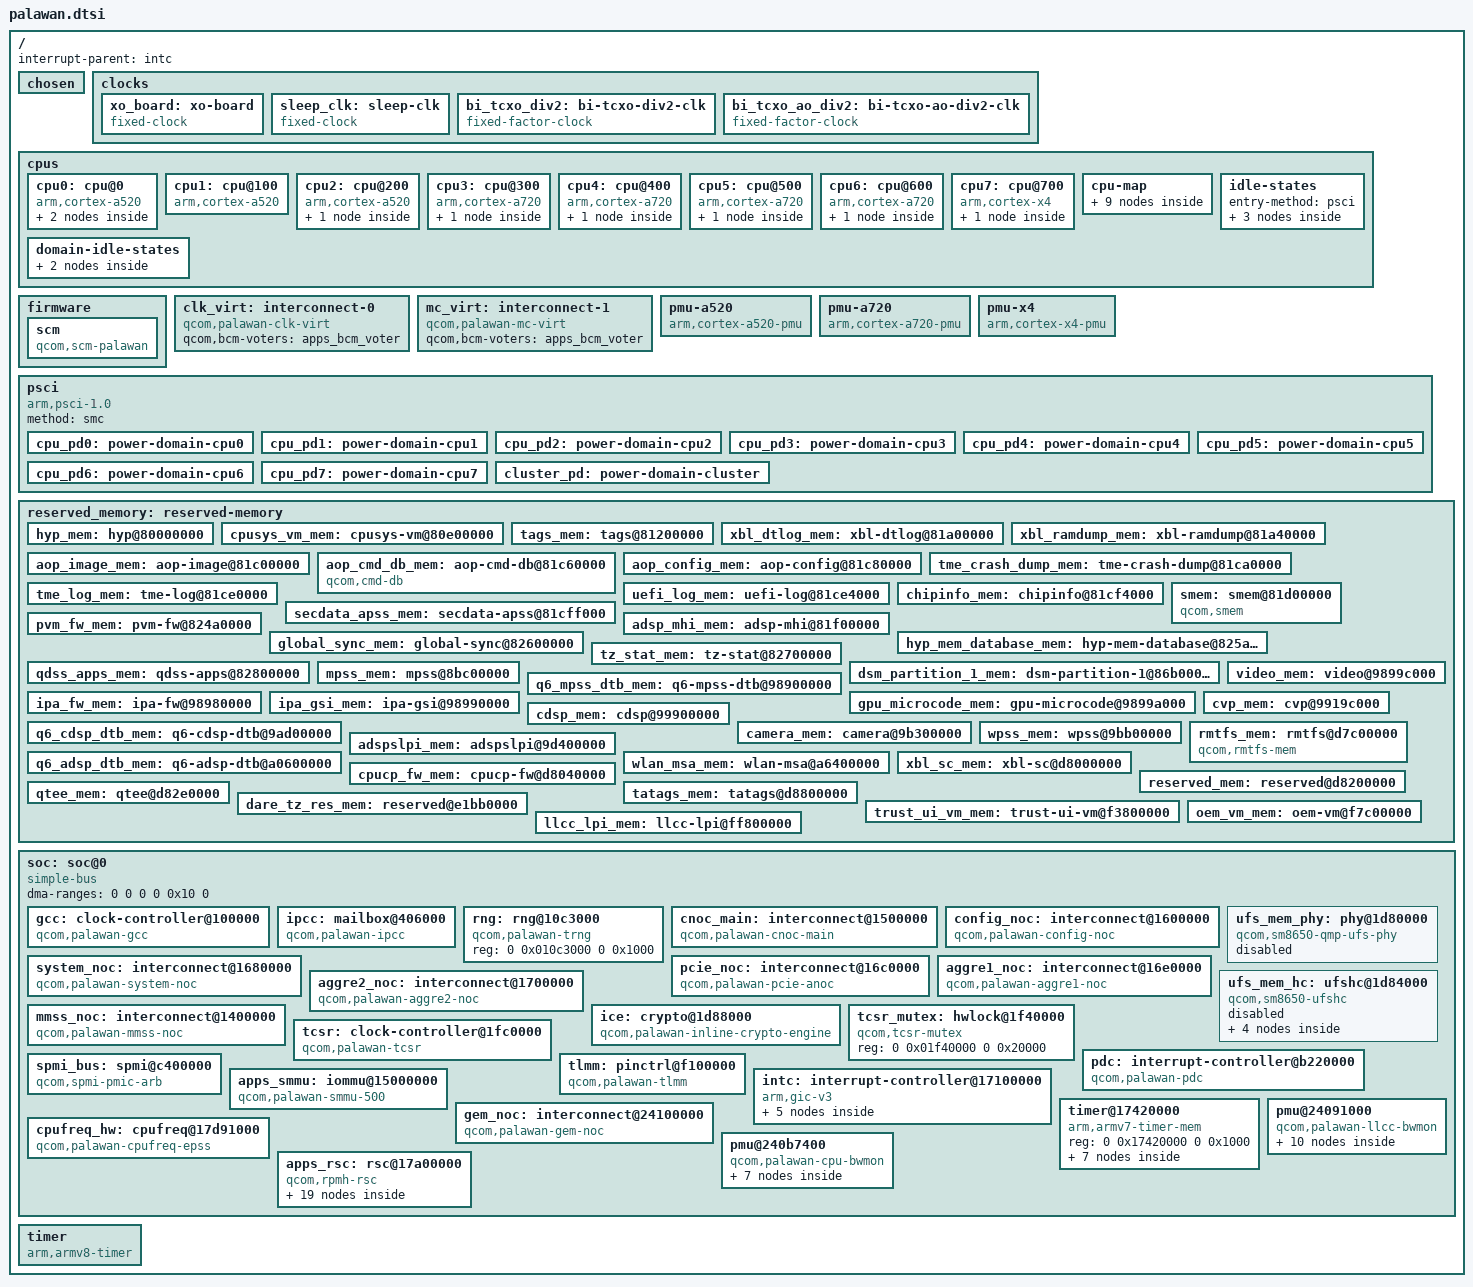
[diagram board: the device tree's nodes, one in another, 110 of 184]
// SPDX-License-Identifier: BSD-3-Clause
/*
 * Copyright (c) 2025, Alexandr Zubtsov <internal.hellhound@mainlining.org>
 */

#include <dt-bindings/clock/qcom,rpmh.h>
#include <dt-bindings/clock/qcom,palawan-gcc.h>
#include <dt-bindings/clock/qcom,sm8650-tcsr.h>
#include <dt-bindings/firmware/qcom,scm.h>
#include <dt-bindings/interconnect/qcom,icc.h>
#include <dt-bindings/interconnect/qcom,palawan-rpmh.h>
#include <dt-bindings/interrupt-controller/arm-gic.h>
#include <dt-bindings/mailbox/qcom-ipcc.h>
#include <dt-bindings/phy/phy-qcom-qmp.h>
#include <dt-bindings/power/qcom,rpmhpd.h>
#include <dt-bindings/power/qcom-rpmpd.h>
#include <dt-bindings/soc/qcom,rpmh-rsc.h>

/ {
	interrupt-parent = <&intc>;

	#address-cells = <2>;
	#size-cells = <2>;

	chosen { };

	clocks {
		xo_board: xo-board {
			compatible = "fixed-clock";
			#clock-cells = <0>;
		};

		sleep_clk: sleep-clk {
			compatible = "fixed-clock";
			#clock-cells = <0>;
		};

		bi_tcxo_div2: bi-tcxo-div2-clk {
			compatible = "fixed-factor-clock";
			#clock-cells = <0>;

			clocks = <&rpmhcc RPMH_CXO_CLK>;
			clock-mult = <1>;
			clock-div = <2>;
		};

		bi_tcxo_ao_div2: bi-tcxo-ao-div2-clk {
			compatible = "fixed-factor-clock";
			#clock-cells = <0>;

			clocks = <&rpmhcc RPMH_CXO_CLK_A>;
			clock-mult = <1>;
			clock-div = <2>;
		};
	};

	cpus {
		#address-cells = <2>;
		#size-cells = <0>;

		cpu0: cpu@0 {
			device_type = "cpu";
			compatible = "arm,cortex-a520";
			reg = <0 0>;

			clocks = <&cpufreq_hw 0>;

			power-domains = <&cpu_pd0>;
			power-domain-names = "psci";

			enable-method = "psci";
			next-level-cache = <&l2_0>;
			capacity-dmips-mhz = <1024>;
			dynamic-power-coefficient = <100>;

			qcom,freq-domain = <&cpufreq_hw 0>;

			#cooling-cells = <2>;

			l2_0: l2-cache {
				compatible = "cache";
				cache-level = <2>;
				cache-unified;
				next-level-cache = <&l3_0>;

				l3_0: l3-cache {
					compatible = "cache";
					cache-level = <3>;
					cache-unified;
				};
			};
		};

		cpu1: cpu@100 {
			device_type = "cpu";
			compatible = "arm,cortex-a520";
			reg = <0 0x100>;

			clocks = <&cpufreq_hw 0>;

			power-domains = <&cpu_pd1>;
			power-domain-names = "psci";
			enable-method = "psci";

			next-level-cache = <&l2_0>;
			capacity-dmips-mhz = <1024>;
			dynamic-power-coefficient = <100>;

			qcom,freq-domain = <&cpufreq_hw 0>;

			#cooling-cells = <2>;
		};

		cpu2: cpu@200 {
			device_type = "cpu";
			compatible = "arm,cortex-a520";
			reg = <0 0x200>;

			clocks = <&cpufreq_hw 0>;

			power-domains = <&cpu_pd2>;
			power-domain-names = "psci";

			enable-method = "psci";
			next-level-cache = <&l2_200>;
			capacity-dmips-mhz = <1024>;
			dynamic-power-coefficient = <100>;

			qcom,freq-domain = <&cpufreq_hw 0>;

			#cooling-cells = <2>;

			l2_200: l2-cache {
				compatible = "cache";
				cache-level = <2>;
				cache-unified;
				next-level-cache = <&l3_0>;
			};
		};

		cpu3: cpu@300 {
			device_type = "cpu";
			compatible = "arm,cortex-a720";
			reg = <0 0x300>;

			clocks = <&cpufreq_hw 1>;

			power-domains = <&cpu_pd3>;
			power-domain-names = "psci";

			enable-method = "psci";
			next-level-cache = <&l2_300>;
			capacity-dmips-mhz = <1690>;
			dynamic-power-coefficient = <287>;

			qcom,freq-domain = <&cpufreq_hw 1>;
			#cooling-cells = <2>;

			l2_300: l2-cache {
				compatible = "cache";
				cache-level = <2>;
				cache-unified;
				next-level-cache = <&l3_0>;
			};
		};

		cpu4: cpu@400 {
			device_type = "cpu";
			compatible = "arm,cortex-a720";
			reg = <0 0x400>;

			clocks = <&cpufreq_hw 1>;

			power-domains = <&cpu_pd4>;
			power-domain-names = "psci";

			enable-method = "psci";
			next-level-cache = <&l2_400>;
			capacity-dmips-mhz = <1690>;
			dynamic-power-coefficient = <287>;

			qcom,freq-domain = <&cpufreq_hw 1>;

			#cooling-cells = <2>;

			l2_400: l2-cache {
				compatible = "cache";
				cache-level = <2>;
				cache-unified;
				next-level-cache = <&l3_0>;
			};
		};

		cpu5: cpu@500 {
			device_type = "cpu";
			compatible = "arm,cortex-a720";
			reg = <0 0x500>;

			clocks = <&cpufreq_hw 1>;

			power-domains = <&cpu_pd5>;
			power-domain-names = "psci";

			enable-method = "psci";
			next-level-cache = <&l2_500>;
			capacity-dmips-mhz = <1690>;
			dynamic-power-coefficient = <287>;

			qcom,freq-domain = <&cpufreq_hw 1>;
			#cooling-cells = <2>;

			l2_500: l2-cache {
				compatible = "cache";
				cache-level = <2>;
				cache-unified;
				next-level-cache = <&l3_0>;
			};
		};

		cpu6: cpu@600 {
			device_type = "cpu";
			compatible = "arm,cortex-a720";
			reg = <0 0x600>;

			clocks = <&cpufreq_hw 1>;

			power-domains = <&cpu_pd6>;
			power-domain-names = "psci";

			enable-method = "psci";
			next-level-cache = <&l2_600>;
			capacity-dmips-mhz = <1690>;
			dynamic-power-coefficient = <287>;

			qcom,freq-domain = <&cpufreq_hw 1>;

			#cooling-cells = <2>;

			l2_600: l2-cache {
				compatible = "cache";
				cache-level = <2>;
				cache-unified;
				next-level-cache = <&l3_0>;
			};
		};

		cpu7: cpu@700 {
			device_type = "cpu";
			compatible = "arm,cortex-x4";
			reg = <0 0x700>;

			clocks = <&cpufreq_hw 2>;

			power-domains = <&cpu_pd7>;
			power-domain-names = "psci";

			enable-method = "psci";
			next-level-cache = <&l2_700>;
			capacity-dmips-mhz = <1843>;
			dynamic-power-coefficient = <664>;

			qcom,freq-domain = <&cpufreq_hw 2>;
			#cooling-cells = <2>;

			l2_700: l2-cache {
				compatible = "cache";
				cache-level = <2>;
				cache-unified;
				next-level-cache = <&l3_0>;
			};
		};

		cpu-map {
			cluster0 {
				core0 {
					cpu = <&cpu0>;
				};

				core1 {
					cpu = <&cpu1>;
				};

				core2 {
					cpu = <&cpu2>;
				};

				core3 {
					cpu = <&cpu3>;
				};

				core4 {
					cpu = <&cpu4>;
				};

				core5 {
					cpu = <&cpu5>;
				};

				core6 {
					cpu = <&cpu6>;
				};

				core7 {
					cpu = <&cpu7>;
				};
			};
		};

		idle-states {
			entry-method = "psci";

			silver_cpu_sleep_0: cpu-sleep-0-0 {
				compatible = "arm,idle-state";
				idle-state-name = "silver-rail-power-collapse";
				arm,psci-suspend-param = <0x40000004>;
				entry-latency-us = <550>;
				exit-latency-us = <750>;
				min-residency-us = <6700>;
				local-timer-stop;
			};

			gold_cpu_sleep_0: cpu-sleep-1-0 {
				compatible = "arm,idle-state";
				idle-state-name = "gold-rail-power-collapse";
				arm,psci-suspend-param = <0x40000004>;
				entry-latency-us = <550>;
				exit-latency-us = <1050>;
				min-residency-us = <7951>;
				local-timer-stop;
			};

			gold_plus_cpu_sleep_0: cpu-sleep-2-0 {
				compatible = "arm,idle-state";
				idle-state-name = "gold-plus-rail-power-collapse";
				arm,psci-suspend-param = <0x40000004>;
				entry-latency-us = <500>;
				exit-latency-us = <1350>;
				min-residency-us = <7480>;
				local-timer-stop;
			};
		};

		domain-idle-states {
			cluster_sleep_0: cluster-sleep-0 {
				compatible = "domain-idle-state";
				arm,psci-suspend-param = <0x41000044>;
				entry-latency-us = <750>;
				exit-latency-us = <2350>;
				min-residency-us = <9144>;
			};

			cluster_sleep_1: cluster-sleep-1 {
				compatible = "domain-idle-state";
				arm,psci-suspend-param = <0x4100b344>;
				entry-latency-us = <2800>;
				exit-latency-us = <4400>;
				min-residency-us = <10150>;
			};
		};
	};

	firmware {
		scm: scm {
			compatible = "qcom,scm-palawan", "qcom,scm";
			qcom,dload-mode = <&tcsr 0x19000>;
			interconnects = <&aggre2_noc MASTER_CRYPTO QCOM_ICC_TAG_ALWAYS
					 &mc_virt SLAVE_EBI1 QCOM_ICC_TAG_ALWAYS>;
		};
	};

	clk_virt: interconnect-0 {
		compatible = "qcom,palawan-clk-virt";
		#interconnect-cells = <2>;
		qcom,bcm-voters = <&apps_bcm_voter>;
	};

	mc_virt: interconnect-1 {
		compatible = "qcom,palawan-mc-virt";
		#interconnect-cells = <2>;
		qcom,bcm-voters = <&apps_bcm_voter>;
	};

	pmu-a520 {
		compatible = "arm,cortex-a520-pmu";
		interrupts = <GIC_PPI 7 IRQ_TYPE_LEVEL_LOW &ppi_cluster0>;
	};

	pmu-a720 {
		compatible = "arm,cortex-a720-pmu";
		interrupts = <GIC_PPI 7 IRQ_TYPE_LEVEL_LOW &ppi_cluster1>;
	};

	pmu-x4 {
		compatible = "arm,cortex-x4-pmu";
		interrupts = <GIC_PPI 7 IRQ_TYPE_LEVEL_LOW &ppi_cluster2>;
	};

	psci {
		compatible = "arm,psci-1.0";
		method = "smc";

		cpu_pd0: power-domain-cpu0 {
			#power-domain-cells = <0>;
			power-domains = <&cluster_pd>;
			domain-idle-states = <&silver_cpu_sleep_0>;
		};

		cpu_pd1: power-domain-cpu1 {
			#power-domain-cells = <0>;
			power-domains = <&cluster_pd>;
			domain-idle-states = <&silver_cpu_sleep_0>;
		};

		cpu_pd2: power-domain-cpu2 {
			#power-domain-cells = <0>;
			power-domains = <&cluster_pd>;
			domain-idle-states = <&silver_cpu_sleep_0>;
		};

		cpu_pd3: power-domain-cpu3 {
			#power-domain-cells = <0>;
			power-domains = <&cluster_pd>;
			domain-idle-states = <&gold_cpu_sleep_0>;
		};

		cpu_pd4: power-domain-cpu4 {
			#power-domain-cells = <0>;
			power-domains = <&cluster_pd>;
			domain-idle-states = <&gold_cpu_sleep_0>;
		};

		cpu_pd5: power-domain-cpu5 {
			#power-domain-cells = <0>;
			power-domains = <&cluster_pd>;
			domain-idle-states = <&gold_cpu_sleep_0>;
		};

		cpu_pd6: power-domain-cpu6 {
			#power-domain-cells = <0>;
			power-domains = <&cluster_pd>;
			domain-idle-states = <&gold_cpu_sleep_0>;
		};

		cpu_pd7: power-domain-cpu7 {
			#power-domain-cells = <0>;
			power-domains = <&cluster_pd>;
			domain-idle-states = <&gold_plus_cpu_sleep_0>;
		};

		cluster_pd: power-domain-cluster {
			#power-domain-cells = <0>;
			domain-idle-states = <&cluster_sleep_0>,
					     <&cluster_sleep_1>;
		};
	};

	reserved_memory: reserved-memory {
		#address-cells = <2>;
		#size-cells = <2>;
		ranges;

		hyp_mem: hyp@80000000 {
			reg = <0 0x80000000 0 0xe00000>;
			no-map;
		};

		cpusys_vm_mem: cpusys-vm@80e00000 {
			reg = <0 0x80e00000 0 0x400000>;
			no-map;
		};

		tags_mem: tags@81200000 {
			reg = <0 0x81200000 0 0x4e0000>;
			no-map;
		};

		xbl_dtlog_mem: xbl-dtlog@81a00000 {
			reg = <0 0x81a00000 0 0x40000>;
			no-map;
		};

		xbl_ramdump_mem: xbl-ramdump@81a40000 {
			reg = <0 0x81a40000 0 0x1c0000>;
			no-map;
		};

		aop_image_mem: aop-image@81c00000 {
			reg = <0 0x81c00000 0 0x60000>;
			no-map;
		};

		aop_cmd_db_mem: aop-cmd-db@81c60000 {
			compatible = "qcom,cmd-db";
			reg = <0 0x81c60000 0 0x20000>;
			no-map;
		};

		aop_config_mem: aop-config@81c80000 {
			reg = <0 0x81c80000 0 0x20000>;
			no-map;
		};

		tme_crash_dump_mem: tme-crash-dump@81ca0000 {
			reg = <0 0x81ca0000 0 0x40000>;
			no-map;
		};

		tme_log_mem: tme-log@81ce0000 {
			reg = <0 0x81ce0000 0 0x4000>;
			no-map;
		};

		uefi_log_mem: uefi-log@81ce4000 {
			reg = <0 0x81ce4000 0 0x10000>;
			no-map;
		};

		chipinfo_mem: chipinfo@81cf4000 {
			reg = <0 0x81cf4000 0 0x1000>;
			no-map;
		};

		secdata_apss_mem: secdata-apss@81cff000 {
			reg = <0 0x81cff000 0 0x1000>;
			no-map;
		};

		smem: smem@81d00000 {
			compatible = "qcom,smem";
			reg = <0 0x81d00000 0 0x200000>;
			hwlocks = <&tcsr_mutex 3>;
			no-map;
		};

		adsp_mhi_mem: adsp-mhi@81f00000 {
			reg = <0 0x81f00000 0 0x20000>;
			no-map;
		};

		pvm_fw_mem: pvm-fw@824a0000 {
			reg = <0 0x824a0000 0 0x100000>;
			no-map;
		};

		hyp_mem_database_mem: hyp-mem-database@825a0000 {
			reg = <0 0x825a0000 0 0x60000>;
			no-map;
		};

		global_sync_mem: global-sync@82600000 {
			reg = <0 0x82600000 0 0x100000>;
			no-map;
		};

		tz_stat_mem: tz-stat@82700000 {
			reg = <0 0x82700000 0 0x100000>;
			no-map;
		};

		qdss_apps_mem: qdss-apps@82800000 {
			reg = <0 0x82800000 0 0x2000000>;
			no-map;
		};

		dsm_partition_1_mem: dsm-partition-1@86b00000 {
			reg = <0 0x86b00000 0 0x3700000>;
			no-map;
		};

		mpss_mem: mpss@8bc00000 {
			reg = <0 0x8bc00000 0 0xcd00000>;
			no-map;
		};

		q6_mpss_dtb_mem: q6-mpss-dtb@98900000 {
			reg = <0 0x98900000 0 0x80000>;
			no-map;
		};

		ipa_fw_mem: ipa-fw@98980000 {
			reg = <0 0x98980000 0 0x10000>;
			no-map;
		};

		ipa_gsi_mem: ipa-gsi@98990000 {
			reg = <0 0x98990000 0 0xa000>;
			no-map;
		};

		gpu_microcode_mem: gpu-microcode@9899a000 {
			reg = <0 0x9899a000 0 0x2000>;
			no-map;
		};

		video_mem: video@9899c000 {
			reg = <0 0x9899c000 0 0x800000>;
			no-map;
		};

		cvp_mem: cvp@9919c000 {
			reg = <0 0x9919c000 0 0x700000>;
			no-map;
		};

		cdsp_mem: cdsp@99900000 {
			reg = <0 0x99900000 0 0x1400000>;
			no-map;
		};

		q6_cdsp_dtb_mem: q6-cdsp-dtb@9ad00000 {
			reg = <0 0x9ad00000 0 0x80000>;
			no-map;
		};

		camera_mem: camera@9b300000 {
			reg = <0 0x9b300000 0 0x800000>;
			no-map;
		};

		wpss_mem: wpss@9bb00000 {
			reg = <0 0x9bb00000 0 0x1900000>;
			no-map;
		};

		adspslpi_mem: adspslpi@9d400000 {
			reg = <0 0x9d400000 0 0x4200000>;
			no-map;
		};

		q6_adsp_dtb_mem: q6-adsp-dtb@a0600000 {
			reg = <0 0xa2600000 0 0x80000>;
			no-map;
		};

		wlan_msa_mem: wlan-msa@a6400000 {
			reg = <0 0xa6400000 0 0xc00000>;
			no-map;
		};

		rmtfs_mem: rmtfs@d7c00000 {
			compatible = "qcom,rmtfs-mem";
			reg = <0 0xd7c00000 0 0x400000>;
			no-map;

			qcom,client-id = <1>;
			qcom,vmid = <QCOM_SCM_VMID_MSS_MSA>;
		};

		xbl_sc_mem: xbl-sc@d8000000 {
			reg = <0 0xd8000000 0 0x40000>;
			no-map;
		};

		cpucp_fw_mem: cpucp-fw@d8040000 {
			reg = <0 0xd8040000 0 0x1c0000>;
			no-map;
		};

		reserved_mem: reserved@d8200000 {
			reg = <0 0xd8200000 0 0xe0000>;
			no-map;
		};

		qtee_mem: qtee@d82e0000 {
			reg = <0 0xd82e0000 0 0x520000>;
			no-map;
		};

		tatags_mem: tatags@d8800000 {
			reg = <0 0xd8800000 0 0x93b0000>;
			no-map;
		};

		dare_tz_res_mem: reserved@e1bb0000 {
			reg = <0 0xe1bb0000 0 0x190000>;
			no-map;
		};

		trust_ui_vm_mem: trust-ui-vm@f3800000 {
			reg = <0 0xf3800000 0 0x4400000>;
			no-map;
		};

		oem_vm_mem: oem-vm@f7c00000 {
			reg = <0 0xf7c00000 0 0x4c00000>;
			no-map;
		};

		llcc_lpi_mem: llcc-lpi@ff800000 {
			reg = <0 0xff800000 0 0x380000>;
			no-map;
		};
	};

	soc: soc@0 {
		compatible = "simple-bus";

		ranges = <0 0 0 0 0x10 0>;
		dma-ranges = <0 0 0 0 0x10 0>;
		#address-cells = <2>;
		#size-cells = <2>;

		gcc: clock-controller@100000 {
			compatible = "qcom,palawan-gcc";
			reg = <0 0x00100000 0 0x1f4200>;

			clocks = <&bi_tcxo_div2>,
				 <&bi_tcxo_ao_div2>,
				 <&sleep_clk>,
				 <0>,
				 <&ufs_mem_phy 0>,
				 <&ufs_mem_phy 1>,
				 <&ufs_mem_phy 2>,
				 <0>;

			#clock-cells = <1>;
			#reset-cells = <1>;
			#power-domain-cells = <1>;
		};

		ipcc: mailbox@406000 {
			compatible = "qcom,palawan-ipcc", "qcom,ipcc";
			reg = <0 0x00406000 0 0x1000>;

			interrupts = <GIC_SPI 229 IRQ_TYPE_LEVEL_HIGH 0>;
			interrupt-controller;
			#interrupt-cells = <3>;

			#mbox-cells = <2>;
		};

		rng: rng@10c3000 {
			compatible = "qcom,palawan-trng", "qcom,trng";
			reg = <0 0x010c3000 0 0x1000>;
		};

		cnoc_main: interconnect@1500000 {
			compatible = "qcom,palawan-cnoc-main";
			reg = <0 0x01500000 0 0x14400>;
			qcom,bcm-voters = <&apps_bcm_voter>;
			#interconnect-cells = <2>;
		};

		config_noc: interconnect@1600000 {
			compatible = "qcom,palawan-config-noc";
			reg = <0 0x01600000 0 0x6900>;
			qcom,bcm-voters = <&apps_bcm_voter>;
			#interconnect-cells = <2>;
		};

		system_noc: interconnect@1680000 {
			compatible = "qcom,palawan-system-noc";
			reg = <0 0x01680000 0 0x40000>;
			qcom,bcm-voters = <&apps_bcm_voter>;
			#interconnect-cells = <2>;
		};

		pcie_noc: interconnect@16c0000 {
			compatible = "qcom,palawan-pcie-anoc";
			reg = <0 0x016c0000 0 0x12400>;
			clocks = <&gcc GCC_AGGRE_NOC_PCIE_AXI_CLK>,
				 <&gcc GCC_CFG_NOC_PCIE_ANOC_AHB_CLK>;
			qcom,bcm-voters = <&apps_bcm_voter>;
			#interconnect-cells = <2>;
		};

		aggre1_noc: interconnect@16e0000 {
			compatible = "qcom,palawan-aggre1-noc";
			reg = <0 0x016e0000 0 0x19180>;
			clocks = <&gcc GCC_AGGRE_UFS_PHY_AXI_CLK>,
				 <&gcc GCC_AGGRE_USB3_PRIM_AXI_CLK>;
			qcom,bcm-voters = <&apps_bcm_voter>;
			#interconnect-cells = <2>;
		};

		aggre2_noc: interconnect@1700000 {
			compatible = "qcom,palawan-aggre2-noc";
			reg = <0 0x01700000 0 0x1e500>;
			clocks = <&rpmhcc RPMH_IPA_CLK>;
			qcom,bcm-voters = <&apps_bcm_voter>;
			#interconnect-cells = <2>;
		};

		mmss_noc: interconnect@1400000 {
			compatible = "qcom,palawan-mmss-noc";
			reg = <0 0x01400000 0 0xdc000>;
			qcom,bcm-voters = <&apps_bcm_voter>;
			#interconnect-cells = <2>;
		};

		ufs_mem_phy: phy@1d80000 {
			compatible = "qcom,sm8650-qmp-ufs-phy";
			reg = <0 0x01d80000 0 0x2000>;

			clocks = <&rpmhcc RPMH_CXO_CLK>,
				 <&gcc GCC_UFS_PHY_PHY_AUX_CLK>,
				 <&tcsr TCSR_UFS_CLKREF_EN>;
			clock-names = "ref",
				      "ref_aux",
				      "qref";

			resets = <&ufs_mem_hc 0>;
			reset-names = "ufsphy";

			power-domains = <&gcc UFS_MEM_PHY_GDSC>;

			#clock-cells = <1>;
			#phy-cells = <0>;

			status = "disabled";
		};

		ufs_mem_hc: ufshc@1d84000 {
			compatible = "qcom,sm8650-ufshc", "qcom,ufshc", "jedec,ufs-2.0";
			reg = <0 0x01d84000 0 0x3000>;

			interrupts = <GIC_SPI 265 IRQ_TYPE_LEVEL_HIGH 0>;

			clocks = <&gcc GCC_UFS_PHY_AXI_CLK>,
				 <&gcc GCC_AGGRE_UFS_PHY_AXI_CLK>,
				 <&gcc GCC_UFS_PHY_AHB_CLK>,
				 <&gcc GCC_UFS_PHY_UNIPRO_CORE_CLK>,
				 <&tcsr TCSR_UFS_PAD_CLKREF_EN>,
				 <&gcc GCC_UFS_PHY_TX_SYMBOL_0_CLK>,
				 <&gcc GCC_UFS_PHY_RX_SYMBOL_0_CLK>,
				 <&gcc GCC_UFS_PHY_RX_SYMBOL_1_CLK>;
			clock-names = "core_clk",
				      "bus_aggr_clk",
				      "iface_clk",
				      "core_clk_unipro",
				      "ref_clk",
				      "tx_lane0_sync_clk",
				      "rx_lane0_sync_clk",
				      "rx_lane1_sync_clk";

			resets = <&gcc GCC_UFS_PHY_BCR>;
			reset-names = "rst";

			interconnects = <&aggre1_noc MASTER_UFS_MEM QCOM_ICC_TAG_ALWAYS
					 &mc_virt SLAVE_EBI1 QCOM_ICC_TAG_ALWAYS>,
					<&gem_noc MASTER_APPSS_PROC QCOM_ICC_TAG_ACTIVE_ONLY
					 &config_noc SLAVE_UFS_MEM_CFG QCOM_ICC_TAG_ACTIVE_ONLY>;
			interconnect-names = "ufs-ddr",
					     "cpu-ufs";

			power-domains = <&gcc UFS_PHY_GDSC>;
			required-opps = <&rpmhpd_opp_nom>;

			operating-points-v2 = <&ufs_opp_table>;

			iommus = <&apps_smmu 0x60 0>;

			lanes-per-direction = <2>;
			qcom,ice = <&ice>;

			phys = <&ufs_mem_phy>;
			phy-names = "ufsphy";

			#reset-cells = <1>;

			status = "disabled";

			ufs_opp_table: opp-table {
				compatible = "operating-points-v2";

				opp-100000000 {
					opp-hz = /bits/ 64 <100000000>,
						 /bits/ 64 <0>,
						 /bits/ 64 <0>,
						 /bits/ 64 <100000000>,
						 /bits/ 64 <0>,
						 /bits/ 64 <0>,
						 /bits/ 64 <0>,
						 /bits/ 64 <0>;
					required-opps = <&rpmhpd_opp_low_svs>;
				};

				opp-201500000 {
					opp-hz = /bits/ 64 <201500000>,
						 /bits/ 64 <0>,
						 /bits/ 64 <0>,
						 /bits/ 64 <201500000>,
						 /bits/ 64 <0>,
						 /bits/ 64 <0>,
						 /bits/ 64 <0>,
						 /bits/ 64 <0>;
					required-opps = <&rpmhpd_opp_svs>;
				};

				opp-403000000 {
					opp-hz = /bits/ 64 <403000000>,
						 /bits/ 64 <0>,
						 /bits/ 64 <0>,
						 /bits/ 64 <403000000>,
						 /bits/ 64 <0>,
						 /bits/ 64 <0>,
						 /bits/ 64 <0>,
						 /bits/ 64 <0>;
					required-opps = <&rpmhpd_opp_nom>;
				};
			};
		};

		ice: crypto@1d88000 {
			compatible = "qcom,palawan-inline-crypto-engine", "qcom,inline-crypto-engine";
			reg = <0 0x01d88000 0 0x18000>;

			clocks = <&gcc GCC_UFS_PHY_ICE_CORE_CLK>;
		};

		tcsr_mutex: hwlock@1f40000 {
			compatible = "qcom,tcsr-mutex";
			reg = <0 0x01f40000 0 0x20000>;
			#hwlock-cells = <1>;
		};

		tcsr: clock-controller@1fc0000 {
			compatible = "qcom,palawan-tcsr", "syscon";
			reg = <0 0x01fc0000 0 0xa0000>;

			clocks = <&rpmhcc RPMH_CXO_CLK>;

			#clock-cells = <1>;
			#reset-cells = <1>;
		};

		pdc: interrupt-controller@b220000 {
			compatible = "qcom,palawan-pdc", "qcom,pdc";
			reg = <0 0x0b220000 0 0x30000>, <0 0x174000f0 0 0x64>;

			interrupt-parent = <&intc>;

			qcom,pdc-ranges = <0 480 94>, <94 609 31>,
					  <125 63 1>, <126 716 12>,
					  <138 251 5>, <143 244 4>;

			#interrupt-cells = <2>;
			interrupt-controller;
		};

		spmi_bus: spmi@c400000 {
			compatible = "qcom,spmi-pmic-arb";
			reg = <0 0x0c400000 0 0x3000>,
			      <0 0x0c500000 0 0x400000>,
			      <0 0x0c440000 0 0x80000>,
			      <0 0x0c4c0000 0 0x10000>,
			      <0 0x0c42d000 0 0x4000>;
			reg-names = "core",
				    "chnls",
				    "obsrvr",
				    "intr",
				    "cnfg";

			interrupts-extended = <&pdc 1 IRQ_TYPE_LEVEL_HIGH 0>;
			interrupt-names = "periph_irq";

			qcom,ee = <0>;
			qcom,channel = <0>;
			qcom,bus-id = <0>;

			interrupt-controller;
			#interrupt-cells = <4>;

			#address-cells = <2>;
			#size-cells = <0>;
		};

		tlmm: pinctrl@f100000 {
			compatible = "qcom,palawan-tlmm";
			reg = <0 0x0f100000 0 0x300000>;

			interrupts = <GIC_SPI 208 IRQ_TYPE_LEVEL_HIGH 0>;

			gpio-controller;
			#gpio-cells = <2>;

			interrupt-controller;
			#interrupt-cells = <2>;

			gpio-ranges = <&tlmm 0 0 179>;

			wakeup-parent = <&pdc>;
		};

		apps_smmu: iommu@15000000 {
			compatible = "qcom,palawan-smmu-500", "qcom,smmu-500", "arm,mmu-500";
			reg = <0 0x15000000 0 0x100000>;

			interrupts = <GIC_SPI 65 IRQ_TYPE_LEVEL_HIGH 0>,
				     <GIC_SPI 97 IRQ_TYPE_LEVEL_HIGH 0>,
				     <GIC_SPI 98 IRQ_TYPE_LEVEL_HIGH 0>,
				     <GIC_SPI 99 IRQ_TYPE_LEVEL_HIGH 0>,
				     <GIC_SPI 100 IRQ_TYPE_LEVEL_HIGH 0>,
				     <GIC_SPI 101 IRQ_TYPE_LEVEL_HIGH 0>,
				     <GIC_SPI 102 IRQ_TYPE_LEVEL_HIGH 0>,
				     <GIC_SPI 103 IRQ_TYPE_LEVEL_HIGH 0>,
				     <GIC_SPI 104 IRQ_TYPE_LEVEL_HIGH 0>,
				     <GIC_SPI 105 IRQ_TYPE_LEVEL_HIGH 0>,
				     <GIC_SPI 106 IRQ_TYPE_LEVEL_HIGH 0>,
				     <GIC_SPI 107 IRQ_TYPE_LEVEL_HIGH 0>,
				     <GIC_SPI 108 IRQ_TYPE_LEVEL_HIGH 0>,
				     <GIC_SPI 109 IRQ_TYPE_LEVEL_HIGH 0>,
				     <GIC_SPI 110 IRQ_TYPE_LEVEL_HIGH 0>,
				     <GIC_SPI 111 IRQ_TYPE_LEVEL_HIGH 0>,
				     <GIC_SPI 112 IRQ_TYPE_LEVEL_HIGH 0>,
				     <GIC_SPI 113 IRQ_TYPE_LEVEL_HIGH 0>,
				     <GIC_SPI 114 IRQ_TYPE_LEVEL_HIGH 0>,
				     <GIC_SPI 115 IRQ_TYPE_LEVEL_HIGH 0>,
				     <GIC_SPI 116 IRQ_TYPE_LEVEL_HIGH 0>,
				     <GIC_SPI 117 IRQ_TYPE_LEVEL_HIGH 0>,
				     <GIC_SPI 118 IRQ_TYPE_LEVEL_HIGH 0>,
				     <GIC_SPI 181 IRQ_TYPE_LEVEL_HIGH 0>,
				     <GIC_SPI 182 IRQ_TYPE_LEVEL_HIGH 0>,
				     <GIC_SPI 183 IRQ_TYPE_LEVEL_HIGH 0>,
				     <GIC_SPI 184 IRQ_TYPE_LEVEL_HIGH 0>,
				     <GIC_SPI 185 IRQ_TYPE_LEVEL_HIGH 0>,
				     <GIC_SPI 186 IRQ_TYPE_LEVEL_HIGH 0>,
				     <GIC_SPI 187 IRQ_TYPE_LEVEL_HIGH 0>,
				     <GIC_SPI 188 IRQ_TYPE_LEVEL_HIGH 0>,
				     <GIC_SPI 189 IRQ_TYPE_LEVEL_HIGH 0>,
				     <GIC_SPI 190 IRQ_TYPE_LEVEL_HIGH 0>,
				     <GIC_SPI 191 IRQ_TYPE_LEVEL_HIGH 0>,
				     <GIC_SPI 192 IRQ_TYPE_LEVEL_HIGH 0>,
				     <GIC_SPI 315 IRQ_TYPE_LEVEL_HIGH 0>,
				     <GIC_SPI 316 IRQ_TYPE_LEVEL_HIGH 0>,
				     <GIC_SPI 317 IRQ_TYPE_LEVEL_HIGH 0>,
				     <GIC_SPI 318 IRQ_TYPE_LEVEL_HIGH 0>,
				     <GIC_SPI 319 IRQ_TYPE_LEVEL_HIGH 0>,
				     <GIC_SPI 320 IRQ_TYPE_LEVEL_HIGH 0>,
				     <GIC_SPI 321 IRQ_TYPE_LEVEL_HIGH 0>,
				     <GIC_SPI 322 IRQ_TYPE_LEVEL_HIGH 0>,
				     <GIC_SPI 323 IRQ_TYPE_LEVEL_HIGH 0>,
				     <GIC_SPI 324 IRQ_TYPE_LEVEL_HIGH 0>,
				     <GIC_SPI 325 IRQ_TYPE_LEVEL_HIGH 0>,
				     <GIC_SPI 326 IRQ_TYPE_LEVEL_HIGH 0>,
				     <GIC_SPI 327 IRQ_TYPE_LEVEL_HIGH 0>,
				     <GIC_SPI 328 IRQ_TYPE_LEVEL_HIGH 0>,
				     <GIC_SPI 329 IRQ_TYPE_LEVEL_HIGH 0>,
				     <GIC_SPI 330 IRQ_TYPE_LEVEL_HIGH 0>,
				     <GIC_SPI 331 IRQ_TYPE_LEVEL_HIGH 0>,
				     <GIC_SPI 332 IRQ_TYPE_LEVEL_HIGH 0>,
				     <GIC_SPI 333 IRQ_TYPE_LEVEL_HIGH 0>,
				     <GIC_SPI 334 IRQ_TYPE_LEVEL_HIGH 0>,
				     <GIC_SPI 335 IRQ_TYPE_LEVEL_HIGH 0>,
				     <GIC_SPI 336 IRQ_TYPE_LEVEL_HIGH 0>,
				     <GIC_SPI 337 IRQ_TYPE_LEVEL_HIGH 0>,
				     <GIC_SPI 338 IRQ_TYPE_LEVEL_HIGH 0>,
				     <GIC_SPI 339 IRQ_TYPE_LEVEL_HIGH 0>,
				     <GIC_SPI 340 IRQ_TYPE_LEVEL_HIGH 0>,
				     <GIC_SPI 341 IRQ_TYPE_LEVEL_HIGH 0>,
				     <GIC_SPI 342 IRQ_TYPE_LEVEL_HIGH 0>,
				     <GIC_SPI 343 IRQ_TYPE_LEVEL_HIGH 0>,
				     <GIC_SPI 344 IRQ_TYPE_LEVEL_HIGH 0>,
				     <GIC_SPI 345 IRQ_TYPE_LEVEL_HIGH 0>,
				     <GIC_SPI 395 IRQ_TYPE_LEVEL_HIGH 0>,
				     <GIC_SPI 396 IRQ_TYPE_LEVEL_HIGH 0>,
				     <GIC_SPI 397 IRQ_TYPE_LEVEL_HIGH 0>,
				     <GIC_SPI 398 IRQ_TYPE_LEVEL_HIGH 0>,
				     <GIC_SPI 399 IRQ_TYPE_LEVEL_HIGH 0>,
				     <GIC_SPI 400 IRQ_TYPE_LEVEL_HIGH 0>,
				     <GIC_SPI 401 IRQ_TYPE_LEVEL_HIGH 0>,
				     <GIC_SPI 402 IRQ_TYPE_LEVEL_HIGH 0>,
				     <GIC_SPI 403 IRQ_TYPE_LEVEL_HIGH 0>,
				     <GIC_SPI 404 IRQ_TYPE_LEVEL_HIGH 0>,
				     <GIC_SPI 405 IRQ_TYPE_LEVEL_HIGH 0>,
				     <GIC_SPI 406 IRQ_TYPE_LEVEL_HIGH 0>,
				     <GIC_SPI 407 IRQ_TYPE_LEVEL_HIGH 0>,
				     <GIC_SPI 408 IRQ_TYPE_LEVEL_HIGH 0>,
				     <GIC_SPI 409 IRQ_TYPE_LEVEL_HIGH 0>,
				     <GIC_SPI 418 IRQ_TYPE_LEVEL_HIGH 0>,
				     <GIC_SPI 419 IRQ_TYPE_LEVEL_HIGH 0>,
				     <GIC_SPI 412 IRQ_TYPE_LEVEL_HIGH 0>,
				     <GIC_SPI 421 IRQ_TYPE_LEVEL_HIGH 0>,
				     <GIC_SPI 706 IRQ_TYPE_LEVEL_HIGH 0>,
				     <GIC_SPI 423 IRQ_TYPE_LEVEL_HIGH 0>,
				     <GIC_SPI 424 IRQ_TYPE_LEVEL_HIGH 0>,
				     <GIC_SPI 425 IRQ_TYPE_LEVEL_HIGH 0>,
				     <GIC_SPI 689 IRQ_TYPE_LEVEL_HIGH 0>,
				     <GIC_SPI 690 IRQ_TYPE_LEVEL_HIGH 0>,
				     <GIC_SPI 691 IRQ_TYPE_LEVEL_HIGH 0>,
				     <GIC_SPI 692 IRQ_TYPE_LEVEL_HIGH 0>,
				     <GIC_SPI 693 IRQ_TYPE_LEVEL_HIGH 0>,
				     <GIC_SPI 694 IRQ_TYPE_LEVEL_HIGH 0>,
				     <GIC_SPI 695 IRQ_TYPE_LEVEL_HIGH 0>,
				     <GIC_SPI 696 IRQ_TYPE_LEVEL_HIGH 0>;

			#iommu-cells = <2>;
			#global-interrupts = <1>;

			dma-coherent;
		};

		intc: interrupt-controller@17100000 {
			compatible = "arm,gic-v3";
			reg = <0 0x17100000 0 0x10000>,		/* GICR */
			      <0 0x17180000 0 0x200000>;	/* GICR * 8 */

			interrupts = <GIC_PPI 9 IRQ_TYPE_LEVEL_LOW 0>;
			#interrupt-cells = <4>;
			interrupt-controller;

			#redistributor-regions = <1>;
			redistributor-stride = <0 0x40000>;

			#address-cells = <2>;
			#size-cells = <2>;

			ranges;

			ppi-partitions {
				ppi_cluster0: interrupt-partition-0 {
					affinity = <&cpu0 &cpu1 &cpu2>;
				};

				ppi_cluster1: interrupt-partition-1 {
					affinity = <&cpu3 &cpu4 &cpu5 &cpu6>;
				};

				ppi_cluster2: interrupt-partition-2 {
					affinity = <&cpu7>;
				};
			};

			gic_its: msi-controller@17140000 {
				compatible = "arm,gic-v3-its";
				reg = <0 0x17140000 0 0x20000>;

				msi-controller;
				#msi-cells = <1>;
			};
		};

		timer@17420000 {
			compatible = "arm,armv7-timer-mem";
			reg = <0 0x17420000 0 0x1000>;

			ranges = <0 0 0 0x20000000>;

			#address-cells = <1>;
			#size-cells = <1>;

			frame@17421000 {
				reg = <0x17421000 0x1000>,
				      <0x17422000 0x1000>;

				interrupts = <GIC_SPI 8 IRQ_TYPE_LEVEL_HIGH 0>,
					     <GIC_SPI 6 IRQ_TYPE_LEVEL_HIGH 0>;

				frame-number = <0>;
			};

			frame@17423000 {
				reg = <0x17423000 0x1000>;

				interrupts = <GIC_SPI 9 IRQ_TYPE_LEVEL_HIGH 0>;

				frame-number = <1>;

				status = "disabled";
			};

			frame@17425000 {
				reg = <0x17425000 0x1000>;

				interrupts = <GIC_SPI 10 IRQ_TYPE_LEVEL_HIGH 0>;

				frame-number = <2>;

				status = "disabled";
			};

			frame@17427000 {
				reg = <0x17427000 0x1000>;

				interrupts = <GIC_SPI 11 IRQ_TYPE_LEVEL_HIGH 0>;

				frame-number = <3>;

				status = "disabled";
			};

			frame@17429000 {
				reg = <0x17429000 0x1000>;

				interrupts = <GIC_SPI 12 IRQ_TYPE_LEVEL_HIGH 0>;

				frame-number = <4>;

				status = "disabled";
			};

			frame@1742b000 {
				reg = <0x1742b000 0x1000>;

				interrupts = <GIC_SPI 13 IRQ_TYPE_LEVEL_HIGH 0>;

				frame-number = <5>;

				status = "disabled";
			};

			frame@1742d000 {
				reg = <0x1742d000 0x1000>;

				interrupts = <GIC_SPI 14 IRQ_TYPE_LEVEL_HIGH 0>;

				frame-number = <6>;

				status = "disabled";
			};
		};

		gem_noc: interconnect@24100000 {
			compatible = "qcom,palawan-gem-noc";
			reg = <0 0x24100000 0 0xc3080>;
			qcom,bcm-voters = <&apps_bcm_voter>;
			#interconnect-cells = <2>;
		};

		cpufreq_hw: cpufreq@17d91000 {
			compatible = "qcom,palawan-cpufreq-epss", "qcom,cpufreq-epss";
			reg = <0 0x17d91000 0 0x1000>,
			      <0 0x17d92000 0 0x1000>,
			      <0 0x17d93000 0 0x1000>;

			reg-names = "freq-domain0",
				    "freq-domain1",
				    "freq-domain2";

			interrupts = <GIC_SPI 30 IRQ_TYPE_LEVEL_HIGH 0>,
				     <GIC_SPI 31 IRQ_TYPE_LEVEL_HIGH 0>,
				     <GIC_SPI 19 IRQ_TYPE_LEVEL_HIGH 0>;
			interrupt-names = "dcvsh-irq-0",
					  "dcvsh-irq-1",
					  "dcvsh-irq-2";

			clocks = <&bi_tcxo_div2>,
				 <&gcc GCC_GPLL0>;
			clock-names = "xo",
				      "alternate";

			#freq-domain-cells = <1>;
			#clock-cells = <1>;
		};

		pmu@24091000 {
			compatible = "qcom,palawan-llcc-bwmon", "qcom,sc7280-llcc-bwmon";
			reg = <0 0x24091000 0 0x1000>;
			interrupts = <GIC_SPI 81 IRQ_TYPE_LEVEL_HIGH 0>;
			interconnects = <&mc_virt MASTER_LLCC QCOM_ICC_TAG_ACTIVE_ONLY
					 &mc_virt SLAVE_EBI1 QCOM_ICC_TAG_ACTIVE_ONLY>;

			operating-points-v2 = <&llcc_bwmon_opp_table>;

			llcc_bwmon_opp_table: opp-table {
				compatible = "operating-points-v2";

				opp-0 {
					opp-peak-kBps = <2086000>;
				};

				opp-1 {
					opp-peak-kBps = <2929000>;
				};

				opp-2 {
					opp-peak-kBps = <5931000>;
				};

				opp-3 {
					opp-peak-kBps = <6515000>;
				};

				opp-4 {
					opp-peak-kBps = <7980000>;
				};

				opp-5 {
					opp-peak-kBps = <10437000>;
				};

				opp-6 {
					opp-peak-kBps = <12157000>;
				};

				opp-7 {
					opp-peak-kBps = <14060000>;
				};

				opp-8 {
					opp-peak-kBps = <16113000>;
				};
			};
		};

		pmu@240b7400 {
			compatible = "qcom,palawan-cpu-bwmon", "qcom,sdm845-bwmon";
			reg = <0 0x240b7400 0 0x600>;
			interrupts = <GIC_SPI 581 IRQ_TYPE_LEVEL_HIGH 0>;
			interconnects = <&gem_noc MASTER_APPSS_PROC QCOM_ICC_TAG_ACTIVE_ONLY
					 &gem_noc SLAVE_LLCC QCOM_ICC_TAG_ACTIVE_ONLY>;

			operating-points-v2 = <&cpu_bwmon_opp_table>;

			cpu_bwmon_opp_table: opp-table {
				compatible = "operating-points-v2";

				opp-0 {
					opp-peak-kBps = <4577000>;
				};

				opp-1 {
					opp-peak-kBps = <7110000>;
				};

				opp-2 {
					opp-peak-kBps = <9155000>;
				};

				opp-3 {
					opp-peak-kBps = <12298000>;
				};

				opp-4 {
					opp-peak-kBps = <14236000>;
				};

				opp-5 {
					opp-peak-kBps = <16265000>;
				};
			};
		};

		apps_rsc: rsc@17a00000 {
			compatible = "qcom,rpmh-rsc";
			reg = <0 0x17a00000 0 0x10000>,
			      <0 0x17a10000 0 0x10000>,
			      <0 0x17a20000 0 0x10000>;
			reg-names = "drv-0",
				    "drv-1",
				    "drv-2";

			interrupts = <GIC_SPI 3 IRQ_TYPE_LEVEL_HIGH 0>,
				     <GIC_SPI 4 IRQ_TYPE_LEVEL_HIGH 0>,
				     <GIC_SPI 5 IRQ_TYPE_LEVEL_HIGH 0>;

			qcom,tcs-offset = <0xd00>;
			qcom,drv-id = <2>;
			qcom,tcs-config = <ACTIVE_TCS    3>, <SLEEP_TCS     2>,
					  <WAKE_TCS      2>, <CONTROL_TCS   0>;

			label = "apps_rsc";

			apps_bcm_voter: bcm-voter {
				compatible = "qcom,bcm-voter";
			};

			rpmhcc: clock-controller {
				compatible = "qcom,palawan-rpmh-clk";

				clocks = <&xo_board>;
				clock-names = "xo";

				#clock-cells = <1>;
			};

			rpmhpd: power-controller {
				compatible = "qcom,palawan-rpmhpd";

				operating-points-v2 = <&rpmhpd_opp_table>;

				#power-domain-cells = <1>;

				rpmhpd_opp_table: opp-table {
					compatible = "operating-points-v2";

					rpmhpd_opp_ret: opp-16 {
						opp-level = <RPMH_REGULATOR_LEVEL_RETENTION>;
					};

					rpmhpd_opp_min_svs: opp-48 {
						opp-level = <RPMH_REGULATOR_LEVEL_MIN_SVS>;
					};

					rpmhpd_opp_low_svs_d2: opp-52 {
						opp-level = <RPMH_REGULATOR_LEVEL_LOW_SVS_D2>;
					};

					rpmhpd_opp_low_svs_d1: opp-56 {
						opp-level = <RPMH_REGULATOR_LEVEL_LOW_SVS_D1>;
					};

					rpmhpd_opp_low_svs_d0: opp-60 {
						opp-level = <RPMH_REGULATOR_LEVEL_LOW_SVS_D0>;
					};

					rpmhpd_opp_low_svs: opp-64 {
						opp-level = <RPMH_REGULATOR_LEVEL_LOW_SVS>;
					};

					rpmhpd_opp_low_svs_l1: opp-80 {
						opp-level = <RPMH_REGULATOR_LEVEL_LOW_SVS_L1>;
					};

					rpmhpd_opp_svs: opp-128 {
						opp-level = <RPMH_REGULATOR_LEVEL_SVS>;
					};

					rpmhpd_opp_svs_l0: opp-144 {
						opp-level = <RPMH_REGULATOR_LEVEL_SVS_L0>;
					};

					rpmhpd_opp_svs_l1: opp-192 {
						opp-level = <RPMH_REGULATOR_LEVEL_SVS_L1>;
					};

					rpmhpd_opp_nom: opp-256 {
						opp-level = <RPMH_REGULATOR_LEVEL_NOM>;
					};

					rpmhpd_opp_nom_l1: opp-320 {
						opp-level = <RPMH_REGULATOR_LEVEL_NOM_L1>;
					};

					rpmhpd_opp_nom_l2: opp-336 {
						opp-level = <RPMH_REGULATOR_LEVEL_NOM_L2>;
					};

					rpmhpd_opp_turbo: opp-384 {
						opp-level = <RPMH_REGULATOR_LEVEL_TURBO>;
					};

					rpmhpd_opp_turbo_l1: opp-416 {
						opp-level = <RPMH_REGULATOR_LEVEL_TURBO_L1>;
					};
				};
			};
		};
	};

	timer {
		compatible = "arm,armv8-timer";

		interrupts = <GIC_PPI 13 IRQ_TYPE_LEVEL_LOW 0>,
			     <GIC_PPI 14 IRQ_TYPE_LEVEL_LOW 0>,
			     <GIC_PPI 11 IRQ_TYPE_LEVEL_LOW 0>,
			     <GIC_PPI 12 IRQ_TYPE_LEVEL_LOW 0>;
	};
};
